# PIC16F18877 register map
File version: 1.0
Registers are 8-bit, read-write, reset 0x0 unless marked. A register's access mark holds for its fields unless they carry their own. Offsets are from the block's base; [hi:lo] are bit positions; {n}, {i} and the like mark numbered series.

## REFERENCES — Voltage reference, DAC and SR latch
Base 0x0080090C
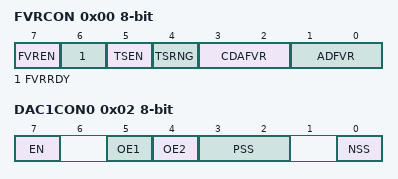
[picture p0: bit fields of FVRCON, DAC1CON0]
0x00 FVRCON (reset mask 0xB0) — FVRCON, data address 0x90c
  [7] FVREN, [6] FVRRDY, [5] TSEN, [4] TSRNG, [3:2] CDAFVR, [1:0] ADFVR
0x02 DAC1CON0 — DAC1CON0, data address 0x90e
  [7] EN, [5] OE1, [4] OE2, [3:2] PSS, [0] NSS
0x03 DAC1CON1 reset not defined — DAC1CON1, data address 0x90f
  [4:0] DAC1R

## SYSTEM — Reset, watchdog and pin options
Base 0x0080080C
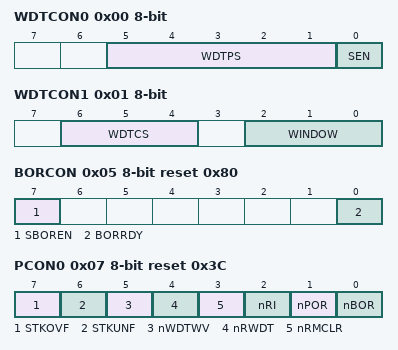
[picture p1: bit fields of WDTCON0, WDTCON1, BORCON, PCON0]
0x00 WDTCON0 (reset mask 0x1) — WDTCON0, data address 0x80c
  [5:1] WDTPS, [0] SEN
0x01 WDTCON1 reset not defined — WDTCON1, data address 0x80d
  [6:4] WDTCS, [2:0] WINDOW
0x05 BORCON reset 0x80 (reset mask 0x80) — BORCON, data address 0x811
  [7] SBOREN, [0] BORRDY
0x06 VREGCON reset 0x1 (reset mask 0x1) — VREGCON, data address 0x812
  [1] VREGPM
0x07 PCON0 reset 0x3C (reset mask 0xFE) — PCON0, data address 0x813
  [7] STKOVF, [6] STKUNF, [5] nWDTWV, [4] nRWDT, [3] nRMCLR, [2] nRI, [1] nPOR, [0] nBOR

## TIMER0
Base 0x0080001C
0x00 TMR0L — TMR0L, data address 0x01c
0x01 TMR0H reset 0xFF — TMR0H, data address 0x01d
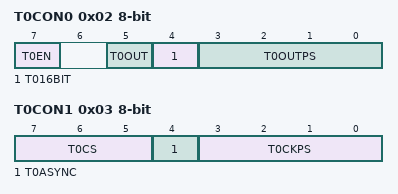
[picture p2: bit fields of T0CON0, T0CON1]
0x02 T0CON0 — T0CON0, data address 0x01e
  [7] T0EN, [5] T0OUT, [4] T016BIT, [3:0] T0OUTPS
0x03 T0CON1 — T0CON1, data address 0x01f
  [7:5] T0CS, [4] T0ASYNC, [3:0] T0CKPS

## TIMER1
Base 0x0080020C
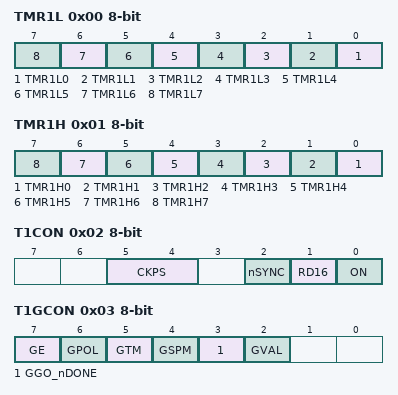
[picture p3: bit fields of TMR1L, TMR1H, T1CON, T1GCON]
0x00 TMR1L reset not defined — TMR1L, data address 0x20c
  [n] TMR1L{n} (n=0..7)
0x01 TMR1H reset not defined — TMR1H, data address 0x20d
  [n] TMR1H{n} (n=0..7)
0x02 T1CON — T1CON, data address 0x20e
  [5:4] CKPS, [2] nSYNC, [1] RD16, [0] ON
0x03 T1GCON (reset mask 0xF8) — T1GCON, data address 0x20f
  [7] GE, [6] GPOL, [5] GTM, [4] GSPM, [3] GGO_nDONE, [2] GVAL
0x04 T1GATE — T1GATE, data address 0x210
  [4:0] GSS
0x05 T1CLK — T1CLK, data address 0x211
  [3:0] CS

## TIMER2
Base 0x0080028E
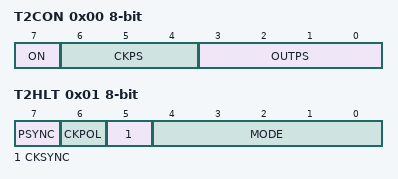
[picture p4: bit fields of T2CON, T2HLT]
0x00 T2CON — T2CON, data address 0x28e
  [7] ON, [6:4] CKPS, [3:0] OUTPS
0x01 T2HLT — T2HLT, data address 0x28f
  [7] PSYNC, [6] CKPOL, [5] CKSYNC, [4:0] MODE
0x02 T2CLKCON — T2CLKCON, data address 0x290
  [3:0] CS
0x03 T2RST — T2RST, data address 0x291
  [4:0] RSEL

## TIMER3
Base 0x00800212
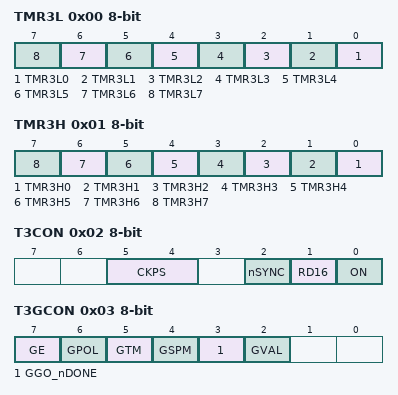
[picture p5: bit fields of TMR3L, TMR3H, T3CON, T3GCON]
0x00 TMR3L reset not defined — TMR3L, data address 0x212
  [n] TMR3L{n} (n=0..7)
0x01 TMR3H reset not defined — TMR3H, data address 0x213
  [n] TMR3H{n} (n=0..7)
0x02 T3CON — T3CON, data address 0x214
  [5:4] CKPS, [2] nSYNC, [1] RD16, [0] ON
0x03 T3GCON (reset mask 0xF8) — T3GCON, data address 0x215
  [7] GE, [6] GPOL, [5] GTM, [4] GSPM, [3] GGO_nDONE, [2] GVAL
0x04 T3GATE — T3GATE, data address 0x216
  [4:0] GSS
0x05 T3CLK — T3CLK, data address 0x217
  [3:0] CS

## TIMER4
Base 0x00800294
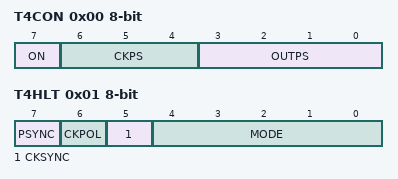
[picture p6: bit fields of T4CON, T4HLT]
0x00 T4CON — T4CON, data address 0x294
  [7] ON, [6:4] CKPS, [3:0] OUTPS
0x01 T4HLT — T4HLT, data address 0x295
  [7] PSYNC, [6] CKPOL, [5] CKSYNC, [4:0] MODE
0x02 T4CLKCON — T4CLKCON, data address 0x296
  [3:0] CS
0x03 T4RST — T4RST, data address 0x297
  [4:0] RSEL

## TIMER5
Base 0x00800218
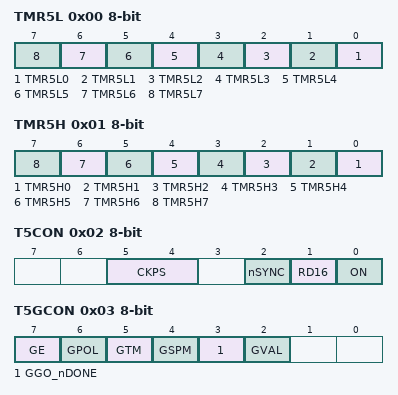
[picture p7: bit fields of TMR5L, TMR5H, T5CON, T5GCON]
0x00 TMR5L reset not defined — TMR5L, data address 0x218
  [n] TMR5L{n} (n=0..7)
0x01 TMR5H reset not defined — TMR5H, data address 0x219
  [n] TMR5H{n} (n=0..7)
0x02 T5CON — T5CON, data address 0x21a
  [5:4] CKPS, [2] nSYNC, [1] RD16, [0] ON
0x03 T5GCON (reset mask 0xF8) — T5GCON, data address 0x21b
  [7] GE, [6] GPOL, [5] GTM, [4] GSPM, [3] GGO_nDONE, [2] GVAL
0x04 T5GATE — T5GATE, data address 0x21c
  [4:0] GSS
0x05 T5CLK — T5CLK, data address 0x21d
  [3:0] CS

## TIMER6
Base 0x0080029A
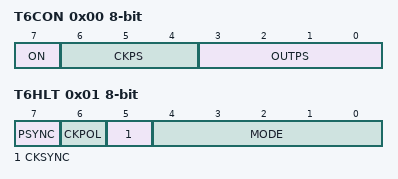
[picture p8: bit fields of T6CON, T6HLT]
0x00 T6CON — T6CON, data address 0x29a
  [7] ON, [6:4] CKPS, [3:0] OUTPS
0x01 T6HLT — T6HLT, data address 0x29b
  [7] PSYNC, [6] CKPOL, [5] CKSYNC, [4:0] MODE
0x02 T6CLKCON — T6CLKCON, data address 0x29c
  [3:0] CS
0x03 T6RST — T6RST, data address 0x29d
  [4:0] RSEL
